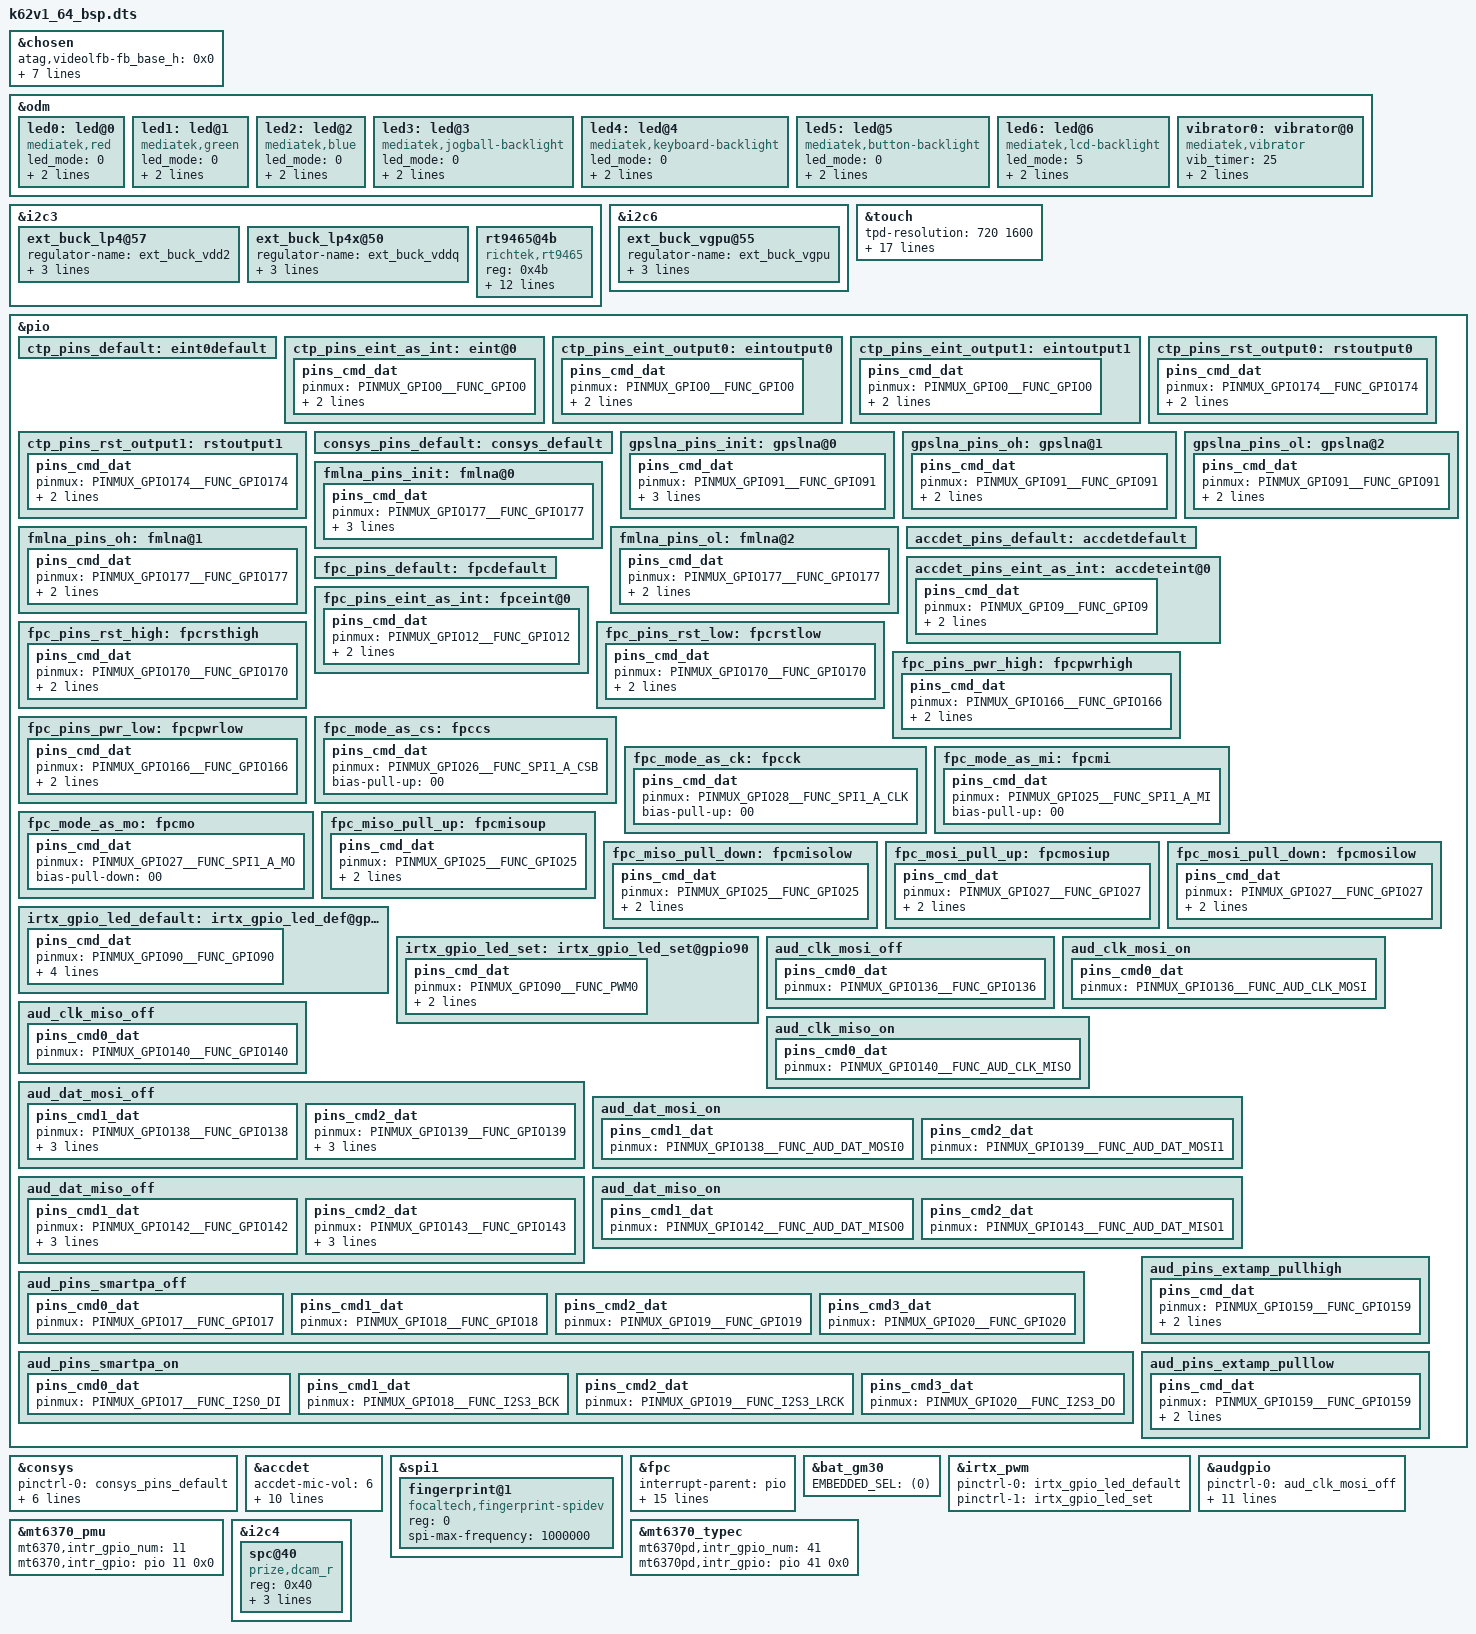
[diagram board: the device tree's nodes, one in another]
/*
 * Copyright (C) 2019 MediaTek Inc.
 *
 * This program is free software; you can redistribute it and/or modify
 * it under the terms of the GNU General Public License version 2 as
 * published by the Free Software Foundation.
 *
 * This program is distributed in the hope that it will be useful,
 * but WITHOUT ANY WARRANTY; without even the implied warranty of
 * MERCHANTABILITY or FITNESS FOR A PARTICULAR PURPOSE.
 * See http://www.gnu.org/licenses/gpl-2.0.html for more details.
 */

#include <dt-bindings/interrupt-controller/arm-gic.h>
#include <dt-bindings/interrupt-controller/irq.h>
#include <dt-bindings/pinctrl/mt6765-pinfunc.h>
#include <dt-bindings/clock/mt6765-clk.h>

/dts-v1/;
/plugin/;

/* chosen */
&chosen {

	/* fpga may has no lk, we need to specify display info here */
	/* fb buffer is reserved using this dts by memory node above */
	atag,videolfb-fb_base_h = <0x0>;
	atag,videolfb-fb_base_l = <0x5e605000>;
	atag,videolfb-islcmfound = <1>;
	/* because no lk, so lcm is not inited */
	atag,videolfb-islcm_inited = <0>;
	atag,videolfb-fps= <6000>;
	atag,videolfb-vramSize= <0x017bb000>;
	atag,videolfb-lcmname= "nt35695B_fhd_dsi_cmd_auo_rt5081_drv";
};

&odm {
	led0:led@0 {
		compatible = "mediatek,red";
		led_mode = <0>;
		data = <1>;
		pwm_config = <0 0 0 0 0>;
	};
	led1:led@1 {
		compatible = "mediatek,green";
		led_mode = <0>;
		data = <1>;
		pwm_config = <0 0 0 0 0>;
	};
	led2:led@2 {
		compatible = "mediatek,blue";
		led_mode = <0>;
		data = <1>;
		pwm_config = <0 0 0 0 0>;
	};
	led3:led@3 {
		compatible = "mediatek,jogball-backlight";
		led_mode = <0>;
		data = <1>;
		pwm_config = <0 0 0 0 0>;
	};
	led4:led@4 {
		compatible = "mediatek,keyboard-backlight";
		led_mode = <0>;
		data = <1>;
		pwm_config = <0 0 0 0 0>;
	};
	led5:led@5 {
		compatible = "mediatek,button-backlight";
		led_mode = <0>;
		data = <1>;
		pwm_config = <0 0 0 0 0>;
	};
	led6:led@6 {
		compatible = "mediatek,lcd-backlight";
		led_mode = <5>;
		data = <1>;
		pwm_config = <0 3 0 0 0>;
	};
	vibrator0:vibrator@0 {
		compatible = "mediatek,vibrator";
		vib_timer = <25>;
		vib_limit = <9>;
		vib_vol= <11>;
	};
};

&i2c3 {
	ext_buck_lp4@57 {
		regulator-name ="ext_buck_vdd2";
		regulator-min-microvolt = <300000>;
		regulator-max-microvolt = <1300000>;
		vsel_pin = <0>;
	};

	ext_buck_lp4x@50 {
		regulator-name ="ext_buck_vddq";
		regulator-min-microvolt = <300000>;
		regulator-max-microvolt = <1300000>;
		vsel_pin = <1>;
	};
};

&i2c6 {
	ext_buck_vgpu@55 {
		regulator-name ="ext_buck_vgpu";
		regulator-min-microvolt = <300000>;
		regulator-max-microvolt = <1300000>;
		vsel_pin = <2>;
	};
};
/* TOUCH start */
&touch {
	tpd-resolution = <720 1600>;
	use-tpd-button = <0>;
	tpd-key-num = <3>;
	tpd-key-local= <139 172 158 0>;
	tpd-key-dim-local = <90 883 100 40 230
				 883 100 40 370 883 100 40 0 0 0 0>;
	tpd-max-touch-num = <5>;
	tpd-filter-enable = <0>;
	tpd-filter-pixel-density = <146>;
	tpd-filter-custom-prameters = <0 0 0 0 0 0 0 0 0 0 0 0>;
	tpd-filter-custom-speed = <0 0 0>;
	pinctrl-names = "default", "state_eint_as_int", "state_eint_output0",
		"state_eint_output1", "state_rst_output0", "state_rst_output1";
	pinctrl-0 = <&ctp_pins_default>;
	pinctrl-1 = <&ctp_pins_eint_as_int>;
	pinctrl-2 = <&ctp_pins_eint_output0>;
	pinctrl-3 = <&ctp_pins_eint_output1>;
	pinctrl-4 = <&ctp_pins_rst_output0>;
	pinctrl-5 = <&ctp_pins_rst_output1>;
	status = "okay";
};
&pio {
	ctp_pins_default: eint0default {
	};
	ctp_pins_eint_as_int: eint@0 {
		pins_cmd_dat {
			pinmux = <PINMUX_GPIO0__FUNC_GPIO0>;
			slew-rate = <0>;
			bias-disable;
		};
	};
	ctp_pins_eint_output0: eintoutput0 {
		pins_cmd_dat {
			pinmux = <PINMUX_GPIO0__FUNC_GPIO0>;
			slew-rate = <1>;
			output-low;
		};
	};
	ctp_pins_eint_output1: eintoutput1 {
		pins_cmd_dat {
			pinmux = <PINMUX_GPIO0__FUNC_GPIO0>;
			slew-rate = <1>;
			output-high;
		};
	};
	ctp_pins_rst_output0: rstoutput0 {
		pins_cmd_dat {
			pinmux = <PINMUX_GPIO174__FUNC_GPIO174>;
			slew-rate = <1>;
			output-low;
		};
	};
	ctp_pins_rst_output1: rstoutput1 {
		pins_cmd_dat {
			pinmux = <PINMUX_GPIO174__FUNC_GPIO174>;
			slew-rate = <1>;
			output-high;
		};
	};
};
/* TOUCH end */

/* CONSYS GPIO standardization */
&pio {
	consys_pins_default: consys_default {
	};
	gpslna_pins_init: gpslna@0 {
		pins_cmd_dat {
			pinmux = <PINMUX_GPIO91__FUNC_GPIO91>;
			slew-rate = <0>;
			bias-disable;
			output-low;
		};
	};
	gpslna_pins_oh: gpslna@1 {
		pins_cmd_dat {
			pinmux = <PINMUX_GPIO91__FUNC_GPIO91>;
			slew-rate = <1>;
			output-high;
		};
	};
	gpslna_pins_ol: gpslna@2 {
		pins_cmd_dat {
			pinmux = <PINMUX_GPIO91__FUNC_GPIO91>;
			slew-rate = <1>;
			output-low;
		};
	};
/*prize-add-pengzhipeng-20191129-start*/
	fmlna_pins_init: fmlna@0 {
		pins_cmd_dat {
			pinmux = <PINMUX_GPIO177__FUNC_GPIO177>;
			slew-rate = <0>;
			bias-disable;
			output-low;
		};
	};
	fmlna_pins_oh: fmlna@1 {
		pins_cmd_dat {
			pinmux = <PINMUX_GPIO177__FUNC_GPIO177>;
			slew-rate = <1>;
			output-high;
		};
	};
	fmlna_pins_ol: fmlna@2 {
		pins_cmd_dat {
			pinmux = <PINMUX_GPIO177__FUNC_GPIO177>;
			slew-rate = <1>;
			output-low;
		};
	};
/*prize-add-pengzhipeng-20191129-end*/
};
/*prize-add-pengzhipeng-20191129-start*/
&consys {
	pinctrl-names = "default", "gps_lna_state_init",
		"gps_lna_state_oh", "gps_lna_state_ol","fm_lna_state_init", "fm_lna_state_oh", "fm_lna_state_ol";
	pinctrl-0 = <&consys_pins_default>;
	pinctrl-1 = <&gpslna_pins_init>;
	pinctrl-2 = <&gpslna_pins_oh>;
	pinctrl-3 = <&gpslna_pins_ol>;
	pinctrl-4 = <&fmlna_pins_init>;
    pinctrl-5 = <&fmlna_pins_oh>;
    pinctrl-6 = <&fmlna_pins_ol>;
	status = "okay";
};
/*prize-add-pengzhipeng-20191129-end*/
/* CONSYS end */

/* accdet start */
&accdet {
	accdet-mic-vol = <6>;
	headset-mode-setting = <0x500 0x500 1 0x1f0 0x800 0x800 0x20 0x44>;
	accdet-plugout-debounce = <1>;
	accdet-mic-mode = <1>;
	headset-eint-level-pol = <8>;
	headset-three-key-threshold = <0 80 206 400>;
	headset-three-key-threshold-CDD = <0 121 192 600>;
	headset-four-key-threshold = <0 58 121 192 400>;
	pinctrl-names = "default", "state_eint_as_int";
	pinctrl-0 = <&accdet_pins_default>;
	pinctrl-1 = <&accdet_pins_eint_as_int>;
	status = "okay";
};
&pio {
	accdet_pins_default: accdetdefault {
	};
	accdet_pins_eint_as_int: accdeteint@0 {
		pins_cmd_dat {
			pinmux = <PINMUX_GPIO9__FUNC_GPIO9>;
			slew-rate = <0>;
			bias-disable;
		};
	};
};
/* accdet end */
/*prize-add-pengzhipeng-20191105-start*/

/* Fingerprint GPIO standardization */
&spi1{
	#address-cells = <1>;
	#size-cells = <0>;
	fingerprint@1{
		compatible = "focaltech,fingerprint-spidev";
		reg = <0>;
		spi-max-frequency = <1000000>;
		status = "okay";
	};
};

&fpc {
	interrupt-parent = <&pio>;
	interrupts = <12 IRQ_TYPE_EDGE_FALLING 12 0>;
	pinctrl-names = "default",
		"fpc_eint_as_int",
		"fpc_pins_rst_high", "fpc_pins_rst_low",
		"fpc_pins_pwr_high", "fpc_pins_pwr_low",
		"fpc_mode_as_cs", "fpc_mode_as_ck",
		"fpc_mode_as_mi", "fpc_mode_as_mo",
		"fpc_miso_pull_up", "fpc_miso_pull_down",
		"fpc_mosi_pull_up", "fpc_mosi_pull_down";
	pinctrl-0 = <&fpc_pins_default>;
	pinctrl-1 = <&fpc_pins_eint_as_int>;
	pinctrl-2 = <&fpc_pins_rst_high>;
	pinctrl-3 = <&fpc_pins_rst_low>;
	pinctrl-4 = <&fpc_pins_pwr_high>;
	pinctrl-5 = <&fpc_pins_pwr_low>;
	pinctrl-6 = <&fpc_mode_as_cs>;
	pinctrl-7 = <&fpc_mode_as_ck>;
	pinctrl-8= <&fpc_mode_as_mi>;
	pinctrl-9 = <&fpc_mode_as_mo>;
	pinctrl-10 = <&fpc_miso_pull_up>;
	pinctrl-11 = <&fpc_miso_pull_down>;
	pinctrl-12 = <&fpc_mosi_pull_up>;
	pinctrl-13 = <&fpc_mosi_pull_down>;
	status = "okay";
};

&pio {
	fpc_pins_default: fpcdefault {
	};

	fpc_pins_eint_as_int: fpceint@0 {
		pins_cmd_dat {
			pinmux = <PINMUX_GPIO12__FUNC_GPIO12>;
			slew-rate = <0>;
			bias-disable;
		};
	};
	fpc_pins_rst_high: fpcrsthigh {
		pins_cmd_dat {
			pinmux = <PINMUX_GPIO170__FUNC_GPIO170>;
			slew-rate = <1>;
			output-high;
		};
	};
	fpc_pins_rst_low: fpcrstlow {
		pins_cmd_dat {
			pinmux = <PINMUX_GPIO170__FUNC_GPIO170>;
			slew-rate = <1>;
			output-low;
		};
	};
	fpc_pins_pwr_high: fpcpwrhigh {
		pins_cmd_dat {
			pinmux = <PINMUX_GPIO166__FUNC_GPIO166>;
			slew-rate = <1>;
			output-high;
		};
	};
	fpc_pins_pwr_low: fpcpwrlow {
		pins_cmd_dat {
			pinmux = <PINMUX_GPIO166__FUNC_GPIO166>;
			slew-rate = <1>;
			output-low;
		};
	};	
	fpc_mode_as_cs: fpccs {
		pins_cmd_dat {
			pinmux = <PINMUX_GPIO26__FUNC_SPI1_A_CSB>;
			bias-pull-up = <00>;
		};
	};
	fpc_mode_as_ck: fpcck {
		pins_cmd_dat {
			pinmux = <PINMUX_GPIO28__FUNC_SPI1_A_CLK>;
			bias-pull-up = <00>;
		};
	};
	fpc_mode_as_mi: fpcmi {
		pins_cmd_dat {
			pinmux = <PINMUX_GPIO25__FUNC_SPI1_A_MI>;
			bias-pull-up = <00>;
		};
	};
	fpc_mode_as_mo: fpcmo {
		pins_cmd_dat {
			pinmux = <PINMUX_GPIO27__FUNC_SPI1_A_MO>;
			bias-pull-down = <00>;
		};
	};
	fpc_miso_pull_up: fpcmisoup {
		pins_cmd_dat {
			pinmux = <PINMUX_GPIO25__FUNC_GPIO25>;
			slew-rate = <1>;
			output-high;
		};
	};
	fpc_miso_pull_down: fpcmisolow {
		pins_cmd_dat {
			pinmux = <PINMUX_GPIO25__FUNC_GPIO25>;
			slew-rate = <1>;
			output-low;
		};
	};
	fpc_mosi_pull_up: fpcmosiup {
		pins_cmd_dat {
			pinmux = <PINMUX_GPIO27__FUNC_GPIO27>;
			slew-rate = <1>;
			output-high;
		};
	};
	fpc_mosi_pull_down: fpcmosilow {
		pins_cmd_dat {
			pinmux = <PINMUX_GPIO27__FUNC_GPIO27>;
			slew-rate = <1>;
			output-low;
		};
	};
};
/* Fingerprint GPIO end */
/*prize-add-pengzhipeng-20191105-end*/
/* battery end */
&bat_gm30 {
	EMBEDDED_SEL = <(0)>;
};
/* battery end */

/* IRTX GPIO end */
&irtx_pwm {
	pinctrl-names = "irtx_gpio_led_default", "irtx_gpio_led_set";
	pinctrl-0 = <&irtx_gpio_led_default>;
	pinctrl-1 = <&irtx_gpio_led_set>;
	status = "okay";
};
&pio {
	irtx_gpio_led_default:irtx_gpio_led_def@gpio90 {
		pins_cmd_dat {
			pinmux = <PINMUX_GPIO90__FUNC_GPIO90>;
			slew-rate = <1>;
			bias-disable;
			output-low;
			input-schmitt-enable = <0>;
		};
	};

	irtx_gpio_led_set:irtx_gpio_led_set@gpio90 {
		pins_cmd_dat {
			pinmux = <PINMUX_GPIO90__FUNC_PWM0>;
			slew-rate = <1>;
			output-high;
		};
	};
};
/* IRTX GPIO Settings -End */

/* AUDIO GPIO standardization */
&audgpio {
	pinctrl-names = "aud_clk_mosi_off",
			"aud_clk_mosi_on",
			"aud_clk_miso_off",
			"aud_clk_miso_on",
			"aud_dat_mosi_off",
			"aud_dat_mosi_on",
			"aud_dat_miso_off",
			"aud_dat_miso_on",
			"aud_smartpa_off",
			"aud_smartpa_on",
			"extamp-pullhigh",
			"extamp-pulllow";
	pinctrl-0 = <&aud_clk_mosi_off>;
	pinctrl-1 = <&aud_clk_mosi_on>;
	pinctrl-2 = <&aud_clk_miso_off>;
	pinctrl-3 = <&aud_clk_miso_on>;
	pinctrl-4 = <&aud_dat_mosi_off>;
	pinctrl-5 = <&aud_dat_mosi_on>;
	pinctrl-6 = <&aud_dat_miso_off>;
	pinctrl-7 = <&aud_dat_miso_on>;
	pinctrl-8 = <&aud_pins_smartpa_off>;
	pinctrl-9 = <&aud_pins_smartpa_on>;
	pinctrl-10 = <&aud_pins_extamp_pullhigh>;
	pinctrl-11 = <&aud_pins_extamp_pulllow>;
	status = "okay";
};

&pio {
	aud_clk_mosi_off: aud_clk_mosi_off {
		pins_cmd0_dat {
			pinmux = <PINMUX_GPIO136__FUNC_GPIO136>;
		};
	};

	aud_clk_mosi_on: aud_clk_mosi_on {
		pins_cmd0_dat {
			pinmux = <PINMUX_GPIO136__FUNC_AUD_CLK_MOSI>;
		};
	};

	aud_clk_miso_off: aud_clk_miso_off {
		pins_cmd0_dat {
			pinmux = <PINMUX_GPIO140__FUNC_GPIO140>;
		};
	};

	aud_clk_miso_on: aud_clk_miso_on {
		pins_cmd0_dat {
			pinmux = <PINMUX_GPIO140__FUNC_AUD_CLK_MISO>;
		};
	};

	aud_dat_mosi_off: aud_dat_mosi_off {
		pins_cmd1_dat {
			pinmux = <PINMUX_GPIO138__FUNC_GPIO138>;
			input-enable;
			slew-rate = <0>;
			bias-disable;
		};
		pins_cmd2_dat {
			pinmux = <PINMUX_GPIO139__FUNC_GPIO139>;
			input-enable;
			slew-rate = <0>;
			bias-disable;
		};
	};

	aud_dat_mosi_on: aud_dat_mosi_on {
		pins_cmd1_dat {
			pinmux = <PINMUX_GPIO138__FUNC_AUD_DAT_MOSI0>;
		};
		pins_cmd2_dat {
			pinmux = <PINMUX_GPIO139__FUNC_AUD_DAT_MOSI1>;
		};
	};

	aud_dat_miso_off: aud_dat_miso_off {
		pins_cmd1_dat {
			pinmux = <PINMUX_GPIO142__FUNC_GPIO142>;
			input-enable;
			slew-rate = <0>;
			bias-disable;
		};
		pins_cmd2_dat {
			pinmux = <PINMUX_GPIO143__FUNC_GPIO143>;
			input-enable;
			slew-rate = <0>;
			bias-disable;
		};
	};

	aud_dat_miso_on: aud_dat_miso_on {
		pins_cmd1_dat {
			pinmux = <PINMUX_GPIO142__FUNC_AUD_DAT_MISO0>;
		};
		pins_cmd2_dat {
			pinmux = <PINMUX_GPIO143__FUNC_AUD_DAT_MISO1>;
		};
	};

	aud_pins_smartpa_off: aud_pins_smartpa_off {
		pins_cmd0_dat {
			pinmux = <PINMUX_GPIO17__FUNC_GPIO17>;
		};
		pins_cmd1_dat {
			pinmux = <PINMUX_GPIO18__FUNC_GPIO18>;
		};
		pins_cmd2_dat {
			pinmux = <PINMUX_GPIO19__FUNC_GPIO19>;
		};
		pins_cmd3_dat {
			pinmux = <PINMUX_GPIO20__FUNC_GPIO20>;
		};
	};

	aud_pins_smartpa_on: aud_pins_smartpa_on {
		pins_cmd0_dat {
			pinmux = <PINMUX_GPIO17__FUNC_I2S0_DI>;
		};
		pins_cmd1_dat {
			pinmux = <PINMUX_GPIO18__FUNC_I2S3_BCK>;
		};
		pins_cmd2_dat {
			pinmux = <PINMUX_GPIO19__FUNC_I2S3_LRCK>;
		};
		pins_cmd3_dat {
			pinmux = <PINMUX_GPIO20__FUNC_I2S3_DO>;
		};
	};
	aud_pins_extamp_pullhigh: aud_pins_extamp_pullhigh {
		pins_cmd_dat {
			pinmux = <PINMUX_GPIO159__FUNC_GPIO159>;
			slew-rate = <1>;
			output-high;
		};
	};

	aud_pins_extamp_pulllow: aud_pins_extamp_pulllow {
		pins_cmd_dat {
			pinmux = <PINMUX_GPIO159__FUNC_GPIO159>;
			slew-rate = <1>;
			output-low;
		};
	};
};
/* AUDIO end */

&mt6370_pmu {
	mt6370,intr_gpio_num = <11>; /* direct defined GPIO num */
	mt6370,intr_gpio = <&pio 11 0x0>;
};

&mt6370_typec {
	mt6370pd,intr_gpio_num = <41>; /* direct defined GPIO num */
	mt6370pd,intr_gpio = <&pio 41 0x0>;
};


&i2c3 {
	rt9465@4b {
		compatible = "richtek,rt9465";
		reg = <0x4b>;
		status = "okay";
		rt,en_gpio_num = <176>;
		rt,en_gpio = <&pio 176 0x0>;
		rt,intr_gpio_num = <23>; /* direct defined GPIO num */
		rt,intr_gpio = <&pio 23 0x0>;
		interrupt-names = "wdtmri";
		charger_name = "secondary_chg";
		ichg = <1500000>; /* uA */
		mivr = <4500000>; /* uV */
		cv = <4550000>; /* uV */
		ieoc = <700000>; /* uA */
		safety_timer = <12>; /* hour */
		en_st; /* safety timer */
		/* en_te; */
		en_wdt;
	};
};


/*zhengjiang.zhu@Koobee.Camera.Driver  2018/11/2  add for prize double camera gc6133*/
&i2c4 {
	spc@40 {
		compatible = "prize,dcam_r";
		reg = <0x40>;
		pdn_pin = <&pio 107 0>;
		rst_pin = <&pio 109 0>;
		sensor_type = <6133>;	/*DO NOT write 0310*/
	};
};
/*zhengjiang.zhu@Koobee.Camera.Driver  2018/11/2  end for prize double camera gc6133*/
#include <k62v1_64_bsp/cust.dtsi>
#include "cust_mt6765_camera.dtsi"
/*End of this file, DO NOT ADD ANYTHING HERE*/
